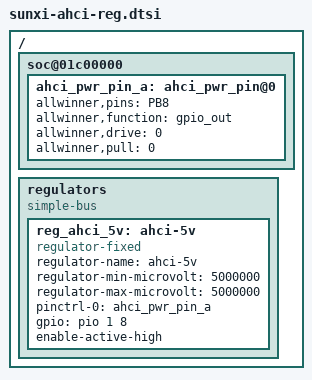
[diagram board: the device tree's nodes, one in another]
/*
 * sunxi boards sata target power supply common code
 *
 * Copyright 2014 - Hans de Goede <hdegoede@redhat.com>
 *
 * The code contained herein is licensed under the GNU General Public
 * License. You may obtain a copy of the GNU General Public License
 * Version 2 or later at the following locations:
 *
 * http://www.opensource.org/licenses/gpl-license.html
 * http://www.gnu.org/copyleft/gpl.html
 */

/ {
	soc@01c00000 {
		ahci_pwr_pin_a: ahci_pwr_pin@0 {
			allwinner,pins = "PB8";
			allwinner,function = "gpio_out";
			allwinner,drive = <0>;
			allwinner,pull = <0>;
		};
	};

	regulators {
		compatible = "simple-bus";
		pinctrl-names = "default";

		reg_ahci_5v: ahci-5v {
			compatible = "regulator-fixed";
			regulator-name = "ahci-5v";
			regulator-min-microvolt = <5000000>;
			regulator-max-microvolt = <5000000>;
			pinctrl-0 = <&ahci_pwr_pin_a>;
			gpio = <&pio 1 8 0>;
			enable-active-high;
		};
	};
};
